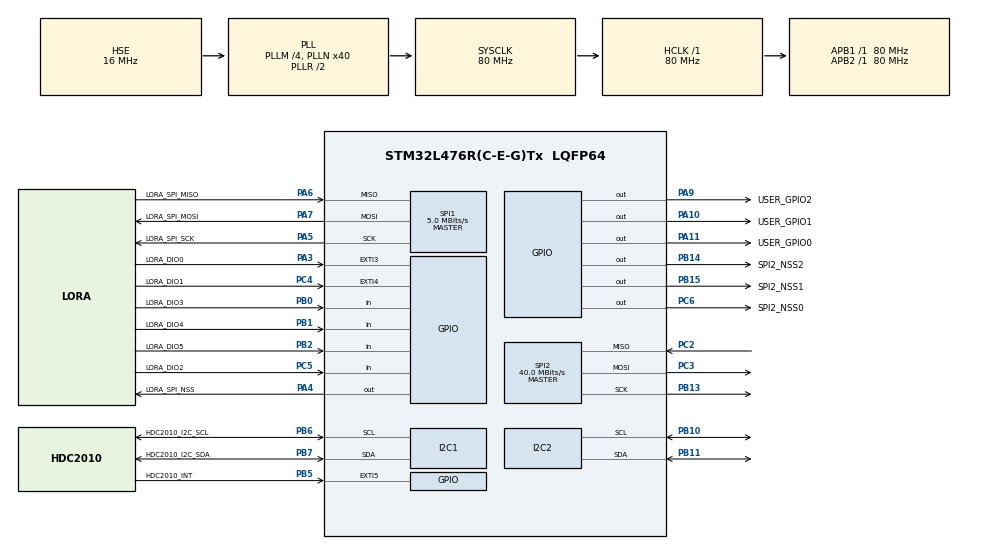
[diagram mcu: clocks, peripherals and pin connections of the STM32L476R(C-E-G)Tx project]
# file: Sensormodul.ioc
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FREERTOS.BinarySemaphores01=TemperatureSemaphore,Dynamic,NULL;HumiditySemaphore,Dynamic,NULL
FREERTOS.Queues01=TemperatureQueue,5,uint32_t,0,Dynamic,NULL,NULL;HumidityQueue,5,uint32_t,0,Dynamic,NULL,NULL
FREERTOS.Tasks01=defaultTask,0,128,StartDefaultTask,Default,NULL,Dynamic,NULL,NULL;RadioTask,2,512,RadioTaskFunction,As weak,NULL,Dynamic,NULL,NULL;SensorsTask,1,512,SensorsTaskFunction,As weak,NULL,Dynamic,NULL,NULL
FREERTOS.configTOTAL_HEAP_SIZE=65536
I2C1.Timing=0x10909CEC
I2C2.Timing=0x10909CEC
Mcu.Family=STM32L4
Mcu.Name=STM32L476R(C-E-G)Tx
Mcu.Package=LQFP64
NVIC.EXTI3_IRQn=true\:5\:0\:false\:false\:true\:true\:true
NVIC.EXTI4_IRQn=true\:5\:0\:false\:false\:true\:true\:true
NVIC.EXTI9_5_IRQn=true\:5\:0\:false\:false\:true\:true\:true
NVIC.I2C1_ER_IRQn=true\:5\:0\:false\:false\:true\:true\:true
NVIC.I2C1_EV_IRQn=true\:5\:0\:false\:false\:true\:true\:true
NVIC.PriorityGroup=NVIC_PRIORITYGROUP_4
NVIC.SPI1_IRQn=true\:5\:0\:false\:false\:true\:true\:true
NVIC.TIM1_UP_TIM16_IRQn=true\:0\:0\:false\:false\:true\:false\:false
NVIC.TIM3_IRQn=true\:5\:0\:false\:false\:true\:true\:true
NVIC.TimeBase=TIM1_UP_TIM16_IRQn
NVIC.TimeBaseIP=TIM1
PA10.GPIO_Label=USER_GPIO1
PA10.Signal=GPIO_Output
PA11.GPIO_Label=USER_GPIO0
PA11.Signal=GPIO_Output
PA13\ (JTMS-SWDIO).Mode=Serial_Wire
PA13\ (JTMS-SWDIO).Signal=SYS_JTMS-SWDIO
PA14\ (JTCK-SWCLK).Mode=Serial_Wire
PA14\ (JTCK-SWCLK).Signal=SYS_JTCK-SWCLK
PA3.GPIO_Label=LORA_DIO0
PA3.GPIO_ModeDefaultEXTI=GPIO_MODE_IT_RISING
PA3.Signal=GPXTI3
PA4.GPIO_Label=LORA_SPI_NSS
PA4.Signal=GPIO_Output
PA5.GPIO_Label=LORA_SPI_SCK
PA5.Mode=Full_Duplex_Master
PA5.Signal=SPI1_SCK
PA6.GPIO_Label=LORA_SPI_MISO
PA6.Mode=Full_Duplex_Master
PA6.Signal=SPI1_MISO
PA7.GPIO_Label=LORA_SPI_MOSI
PA7.Mode=Full_Duplex_Master
PA7.Signal=SPI1_MOSI
PA9.GPIO_Label=USER_GPIO2
PA9.Signal=GPIO_Output
PB0.GPIO_Label=LORA_DIO3
PB0.Signal=GPIO_Input
PB1.GPIO_Label=LORA_DIO4
PB1.Signal=GPIO_Input
PB10.Mode=I2C
PB10.Signal=I2C2_SCL
PB11.Mode=I2C
PB11.Signal=I2C2_SDA
PB13.Mode=Full_Duplex_Master
PB13.Signal=SPI2_SCK
PB14.GPIO_Label=SPI2_NSS2
PB14.Signal=GPIO_Output
PB15.GPIO_Label=SPI2_NSS1
PB15.Signal=GPIO_Output
PB2.GPIO_Label=LORA_DIO5
PB2.Signal=GPIO_Input
PB5.GPIO_Label=HDC2010_INT
PB5.Signal=GPXTI5
PB6.GPIO_Label=HDC2010_I2C_SCL
PB6.Mode=I2C
PB6.Signal=I2C1_SCL
PB7.GPIO_Label=HDC2010_I2C_SDA
PB7.Mode=I2C
PB7.Signal=I2C1_SDA
PC2.Mode=Full_Duplex_Master
PC2.Signal=SPI2_MISO
PC3.Mode=Full_Duplex_Master
PC3.Signal=SPI2_MOSI
PC4.GPIO_Label=LORA_DIO1
PC4.GPIO_ModeDefaultEXTI=GPIO_MODE_IT_RISING
PC4.Signal=GPXTI4
PC5.GPIO_Label=LORA_DIO2
PC5.Signal=GPIO_Input
PC6.GPIO_Label=SPI2_NSS0
PC6.Signal=GPIO_Output
PH0-OSC_IN\ (PH0).Mode=HSE-External-Oscillator
PH0-OSC_IN\ (PH0).Signal=RCC_OSC_IN
PH1-OSC_OUT\ (PH1).Mode=HSE-External-Oscillator
PH1-OSC_OUT\ (PH1).Signal=RCC_OSC_OUT
ProjectManager.HeapSize=0x200
ProjectManager.StackSize=0x400
ProjectManager.TargetToolchain=SW4STM32
RCC.ADCFreq_Value=16000000
RCC.AHBFreq_Value=80000000
RCC.APB1Freq_Value=80000000
RCC.APB1TimFreq_Value=80000000
RCC.APB2Freq_Value=80000000
RCC.APB2TimFreq_Value=80000000
RCC.CortexFreq_Value=80000000
RCC.HCLKFreq_Value=80000000
RCC.HSE_VALUE=16000000
RCC.HSI_VALUE=16000000
RCC.LSE_VALUE=32768
RCC.MSI_VALUE=4000000
RCC.PLLM=4
RCC.PLLN=40
RCC.PLLSourceVirtual=RCC_PLLSOURCE_HSE
RCC.SYSCLKFreq_VALUE=80000000
RCC.SYSCLKSource=RCC_SYSCLKSOURCE_PLLCLK
RCC.USBFreq_Value=16000000
RCC.VCOOutputFreq_Value=160000000
SPI1.BaudRatePrescaler=SPI_BAUDRATEPRESCALER_16
SPI1.CalculateBaudRate=5.0 MBits/s
SPI1.DataSize=SPI_DATASIZE_8BIT
SPI1.Direction=SPI_DIRECTION_2LINES
SPI1.Mode=SPI_MODE_MASTER
SPI1.VirtualType=VM_MASTER
SPI2.BaudRatePrescaler=SPI_BAUDRATEPRESCALER_2
SPI2.CalculateBaudRate=40.0 MBits/s
SPI2.Direction=SPI_DIRECTION_2LINES
SPI2.Mode=SPI_MODE_MASTER
SPI2.VirtualType=VM_MASTER
TIM3.AutoReloadPreload=TIM_AUTORELOAD_PRELOAD_ENABLE
TIM3.ClockDivision=TIM_CLOCKDIVISION_DIV1
TIM3.CounterMode=TIM_COUNTERMODE_UP
TIM3.Period=40000
TIM3.Prescaler=1999
VP_FREERTOS_VS_ENABLE.Mode=Enabled
VP_SYS_VS_tim1.Mode=TIM1
VP_TIM3_VS_ClockSourceINT.Mode=Internal
board=custom

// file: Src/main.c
/**
  ******************************************************************************
  * @file           : main.c
  * @brief          : Main program body
  ******************************************************************************
  * This notice applies to any and all portions of this file
  * that are not between comment pairs USER CODE BEGIN and
  * USER CODE END. Other portions of this file, whether
  * inserted by the user or by software development tools
  * are owned by their respective copyright owners.
  *
  * Copyright (c) 2018 STMicroelectronics International N.V.
  * All rights reserved.
  *
  * Redistribution and use in source and binary forms, with or without
  * modification, are permitted, provided that the following conditions are met:
  *
  * 1. Redistribution of source code must retain the above copyright notice,
  *    this list of conditions and the following disclaimer.
  * 2. Redistributions in binary form must reproduce the above copyright notice,
  *    this list of conditions and the following disclaimer in the documentation
  *    and/or other materials provided with the distribution.
  * 3. Neither the name of STMicroelectronics nor the names of other
  *    contributors to this software may be used to endorse or promote products
  *    derived from this software without specific written permission.
  * 4. This software, including modifications and/or derivative works of this
  *    software, must execute solely and exclusively on microcontroller or
  *    microprocessor devices manufactured by or for STMicroelectronics.
  * 5. Redistribution and use of this software other than as permitted under
  *    this license is void and will automatically terminate your rights under
  *    this license.
  *
  * THIS SOFTWARE IS PROVIDED BY STMICROELECTRONICS AND CONTRIBUTORS "AS IS"
  * AND ANY EXPRESS, IMPLIED OR STATUTORY WARRANTIES, INCLUDING, BUT NOT
  * LIMITED TO, THE IMPLIED WARRANTIES OF MERCHANTABILITY, FITNESS FOR A
  * PARTICULAR PURPOSE AND NON-INFRINGEMENT OF THIRD PARTY INTELLECTUAL PROPERTY
  * RIGHTS ARE DISCLAIMED TO THE FULLEST EXTENT PERMITTED BY LAW. IN NO EVENT
  * SHALL STMICROELECTRONICS OR CONTRIBUTORS BE LIABLE FOR ANY DIRECT, INDIRECT,
  * INCIDENTAL, SPECIAL, EXEMPLARY, OR CONSEQUENTIAL DAMAGES (INCLUDING, BUT NOT
  * LIMITED TO, PROCUREMENT OF SUBSTITUTE GOODS OR SERVICES; LOSS OF USE, DATA,
  * OR PROFITS; OR BUSINESS INTERRUPTION) HOWEVER CAUSED AND ON ANY THEORY OF
  * LIABILITY, WHETHER IN CONTRACT, STRICT LIABILITY, OR TORT (INCLUDING
  * NEGLIGENCE OR OTHERWISE) ARISING IN ANY WAY OUT OF THE USE OF THIS SOFTWARE,
  * EVEN IF ADVISED OF THE POSSIBILITY OF SUCH DAMAGE.
  *
  ******************************************************************************
  */
#include "main.h"
#include "stm32l4xx_hal.h"
#include "cmsis_os.h"
#include "i2c.h"
#include "spi.h"
#include "tim.h"
#include "gpio.h"

/* USER CODE BEGIN Includes */
#include "stm32l476xx.h"
#include "stdint.h"
#include "sensors.h"
#include "radio.h"
/* USER CODE END Includes */

/* USER CODE BEGIN PV */
/* Private variables ---------------------------------------------------------*/
/* USER CODE END PV */

void SystemClock_Config(void);
void MX_FREERTOS_Init(void);

/* USER CODE BEGIN PFP */
/* Private function prototypes -----------------------------------------------*/

/* USER CODE END PFP */

int main(void)
{

  /* MCU Configuration----------------------------------------------------------*/

  /* Reset of all peripherals, Initializes the Flash interface and the Systick. */
  HAL_Init();

  /* Configure the system clock */
  SystemClock_Config();

  /* Initialize all configured peripherals */
  MX_GPIO_Init();
  MX_I2C1_Init();
  MX_I2C2_Init();
  MX_SPI1_Init();
  MX_SPI2_Init();
  MX_TIM3_Init();

  /* Call init function for freertos objects (in freertos.c) */
  MX_FREERTOS_Init();

  /* Start scheduler */
  osKernelStart();

  /* We should never get here as control is now taken by the scheduler */

  /* Infinite loop */
  while (1)
  {

  }

}

void SystemClock_Config(void)
{

  RCC_OscInitTypeDef RCC_OscInitStruct;
  RCC_ClkInitTypeDef RCC_ClkInitStruct;
  RCC_PeriphCLKInitTypeDef PeriphClkInit;

    /**Initializes the CPU, AHB and APB busses clocks
    */
  RCC_OscInitStruct.OscillatorType = RCC_OSCILLATORTYPE_HSE;
  RCC_OscInitStruct.HSEState = RCC_HSE_ON;
  RCC_OscInitStruct.PLL.PLLState = RCC_PLL_ON;
  RCC_OscInitStruct.PLL.PLLSource = RCC_PLLSOURCE_HSE;
  RCC_OscInitStruct.PLL.PLLM = 4;
  RCC_OscInitStruct.PLL.PLLN = 40;
  RCC_OscInitStruct.PLL.PLLP = RCC_PLLP_DIV7;
  RCC_OscInitStruct.PLL.PLLQ = RCC_PLLQ_DIV2;
  RCC_OscInitStruct.PLL.PLLR = RCC_PLLR_DIV2;
  if (HAL_RCC_OscConfig(&RCC_OscInitStruct) != HAL_OK)
  {
    _Error_Handler(__FILE__, __LINE__);
  }

    /**Initializes the CPU, AHB and APB busses clocks
    */
  RCC_ClkInitStruct.ClockType = RCC_CLOCKTYPE_HCLK|RCC_CLOCKTYPE_SYSCLK
                              |RCC_CLOCKTYPE_PCLK1|RCC_CLOCKTYPE_PCLK2;
  RCC_ClkInitStruct.SYSCLKSource = RCC_SYSCLKSOURCE_PLLCLK;
  RCC_ClkInitStruct.AHBCLKDivider = RCC_SYSCLK_DIV1;
  RCC_ClkInitStruct.APB1CLKDivider = RCC_HCLK_DIV1;
  RCC_ClkInitStruct.APB2CLKDivider = RCC_HCLK_DIV1;

  if (HAL_RCC_ClockConfig(&RCC_ClkInitStruct, FLASH_LATENCY_4) != HAL_OK)
  {
    _Error_Handler(__FILE__, __LINE__);
  }

  PeriphClkInit.PeriphClockSelection = RCC_PERIPHCLK_I2C1|RCC_PERIPHCLK_I2C2;
  PeriphClkInit.I2c1ClockSelection = RCC_I2C1CLKSOURCE_PCLK1;
  PeriphClkInit.I2c2ClockSelection = RCC_I2C2CLKSOURCE_PCLK1;
  if (HAL_RCCEx_PeriphCLKConfig(&PeriphClkInit) != HAL_OK)
  {
    _Error_Handler(__FILE__, __LINE__);
  }

    /**Configure the main internal regulator output voltage
    */
  if (HAL_PWREx_ControlVoltageScaling(PWR_REGULATOR_VOLTAGE_SCALE1) != HAL_OK)
  {
    _Error_Handler(__FILE__, __LINE__);
  }

    /**Configure the Systick interrupt time
    */
  HAL_SYSTICK_Config(HAL_RCC_GetHCLKFreq()/1000);

    /**Configure the Systick
    */
  HAL_SYSTICK_CLKSourceConfig(SYSTICK_CLKSOURCE_HCLK);

  /* SysTick_IRQn interrupt configuration */
  HAL_NVIC_SetPriority(SysTick_IRQn, 15, 0);
}

void HAL_TIM_PeriodElapsedCallback(TIM_HandleTypeDef *htim)
{
  if (htim->Instance == TIM1) {
    HAL_IncTick();
  }
  /* USER CODE BEGIN Callback 1 */

  if (htim->Instance == TIM3)
  {
	  HAL_TIM_Base_Stop_IT(&htim3);
	  RadioSetState(Tx);
  }
  /* USER CODE END Callback 1 */
}

void _Error_Handler(char *file, int line)
{
  while(1)
  {
  }
}

/************************ (C) COPYRIGHT STMicroelectronics *****END OF FILE****/

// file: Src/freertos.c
/* USER CODE BEGIN Header */
/**
  ******************************************************************************
  * File Name          : freertos.c
  * Description        : Code for freertos applications
  ******************************************************************************
  * This notice applies to any and all portions of this file
  * that are not between comment pairs USER CODE BEGIN and
  * USER CODE END. Other portions of this file, whether
  * inserted by the user or by software development tools
  * are owned by their respective copyright owners.
  *
  * Copyright (c) 2018 STMicroelectronics International N.V.
  * All rights reserved.
  *
  * Redistribution and use in source and binary forms, with or without
  * modification, are permitted, provided that the following conditions are met:
  *
  * 1. Redistribution of source code must retain the above copyright notice,
  *    this list of conditions and the following disclaimer.
  * 2. Redistributions in binary form must reproduce the above copyright notice,
  *    this list of conditions and the following disclaimer in the documentation
  *    and/or other materials provided with the distribution.
  * 3. Neither the name of STMicroelectronics nor the names of other
  *    contributors to this software may be used to endorse or promote products
  *    derived from this software without specific written permission.
  * 4. This software, including modifications and/or derivative works of this
  *    software, must execute solely and exclusively on microcontroller or
  *    microprocessor devices manufactured by or for STMicroelectronics.
  * 5. Redistribution and use of this software other than as permitted under
  *    this license is void and will automatically terminate your rights under
  *    this license.
  *
  * THIS SOFTWARE IS PROVIDED BY STMICROELECTRONICS AND CONTRIBUTORS "AS IS"
  * AND ANY EXPRESS, IMPLIED OR STATUTORY WARRANTIES, INCLUDING, BUT NOT
  * LIMITED TO, THE IMPLIED WARRANTIES OF MERCHANTABILITY, FITNESS FOR A
  * PARTICULAR PURPOSE AND NON-INFRINGEMENT OF THIRD PARTY INTELLECTUAL PROPERTY
  * RIGHTS ARE DISCLAIMED TO THE FULLEST EXTENT PERMITTED BY LAW. IN NO EVENT
  * SHALL STMICROELECTRONICS OR CONTRIBUTORS BE LIABLE FOR ANY DIRECT, INDIRECT,
  * INCIDENTAL, SPECIAL, EXEMPLARY, OR CONSEQUENTIAL DAMAGES (INCLUDING, BUT NOT
  * LIMITED TO, PROCUREMENT OF SUBSTITUTE GOODS OR SERVICES; LOSS OF USE, DATA,
  * OR PROFITS; OR BUSINESS INTERRUPTION) HOWEVER CAUSED AND ON ANY THEORY OF
  * LIABILITY, WHETHER IN CONTRACT, STRICT LIABILITY, OR TORT (INCLUDING
  * NEGLIGENCE OR OTHERWISE) ARISING IN ANY WAY OUT OF THE USE OF THIS SOFTWARE,
  * EVEN IF ADVISED OF THE POSSIBILITY OF SUCH DAMAGE.
  *
  ******************************************************************************
  */
/* USER CODE END Header */

#include "FreeRTOS.h"
#include "task.h"
#include "main.h"
#include "cmsis_os.h"

osThreadId defaultTaskHandle;
osThreadId RadioTaskHandle;
osThreadId SensorsTaskHandle;
osMessageQId TemperatureQueueHandle;
osMessageQId HumidityQueueHandle;
osSemaphoreId TemperatureSemaphoreHandle;
osSemaphoreId HumiditySemaphoreHandle;

void StartDefaultTask(void const * argument);
void RadioTaskFunction(void const * argument);
void SensorsTaskFunction(void const * argument);

void MX_FREERTOS_Init(void); /* (MISRA C 2004 rule 8.1) */

void MX_FREERTOS_Init(void) {

  /* Create the semaphores(s) */
  /* definition and creation of TemperatureSemaphore */
  osSemaphoreDef(TemperatureSemaphore);
  TemperatureSemaphoreHandle = osSemaphoreCreate(osSemaphore(TemperatureSemaphore), 1);

  /* definition and creation of HumiditySemaphore */
  osSemaphoreDef(HumiditySemaphore);
  HumiditySemaphoreHandle = osSemaphoreCreate(osSemaphore(HumiditySemaphore), 1);

  /* Create the thread(s) */
  /* definition and creation of defaultTask */
  osThreadDef(defaultTask, StartDefaultTask, osPriorityNormal, 0, 128);
  defaultTaskHandle = osThreadCreate(osThread(defaultTask), NULL);

  /* definition and creation of RadioTask */
  osThreadDef(RadioTask, RadioTaskFunction, osPriorityHigh, 0, 512);
  RadioTaskHandle = osThreadCreate(osThread(RadioTask), NULL);

  /* definition and creation of SensorsTask */
  osThreadDef(SensorsTask, SensorsTaskFunction, osPriorityAboveNormal, 0, 512);
  SensorsTaskHandle = osThreadCreate(osThread(SensorsTask), NULL);

  /* Create the queue(s) */
  /* definition and creation of TemperatureQueue */
/* what about the sizeof here??? cd native code */
  osMessageQDef(TemperatureQueue, 5, uint32_t);
  TemperatureQueueHandle = osMessageCreate(osMessageQ(TemperatureQueue), NULL);

  /* definition and creation of HumidityQueue */
/* what about the sizeof here??? cd native code */
  osMessageQDef(HumidityQueue, 5, uint32_t);
  HumidityQueueHandle = osMessageCreate(osMessageQ(HumidityQueue), NULL);

}

void StartDefaultTask(void const * argument)
{

  for(;;)
  {
    osDelay(1);
  }
}

__weak void RadioTaskFunction(void const * argument)
{
  for(;;)
  {
    osDelay(1);
  }
}

__weak void SensorsTaskFunction(void const * argument)
{
  for(;;)
  {
    osDelay(1);
  }
}

/************************ (C) COPYRIGHT STMicroelectronics *****END OF FILE****/
